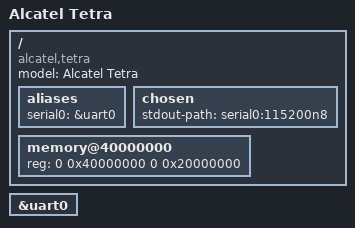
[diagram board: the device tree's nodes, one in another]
// SPDX-License-Identifier: BSD-3-Clause
/*
 * Copyright (c) 2021, Yassine Oudjana <y.oudjana@protonmail.com>
 */

/dts-v1/;

#include "mt6739.dtsi"

/ {
	model = "Alcatel Tetra";
	compatible = "alcatel,tetra",
		     "alcatel,5041c",
		     "mediatek,mt6739";

	aliases {
		serial0 = &uart0;
	};

	chosen {
		#address-cells = <2>;
		#size-cells = <2>;
		ranges;
		stdout-path = "serial0:115200n8";
	};

	memory@40000000 {
		device_type = "memory";
		reg = <0 0x40000000 0 0x20000000>;
	};
};

// uart pins are on board next to main camera
// uart runs at 1.8v
&uart0 {
	status = "okay";
};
